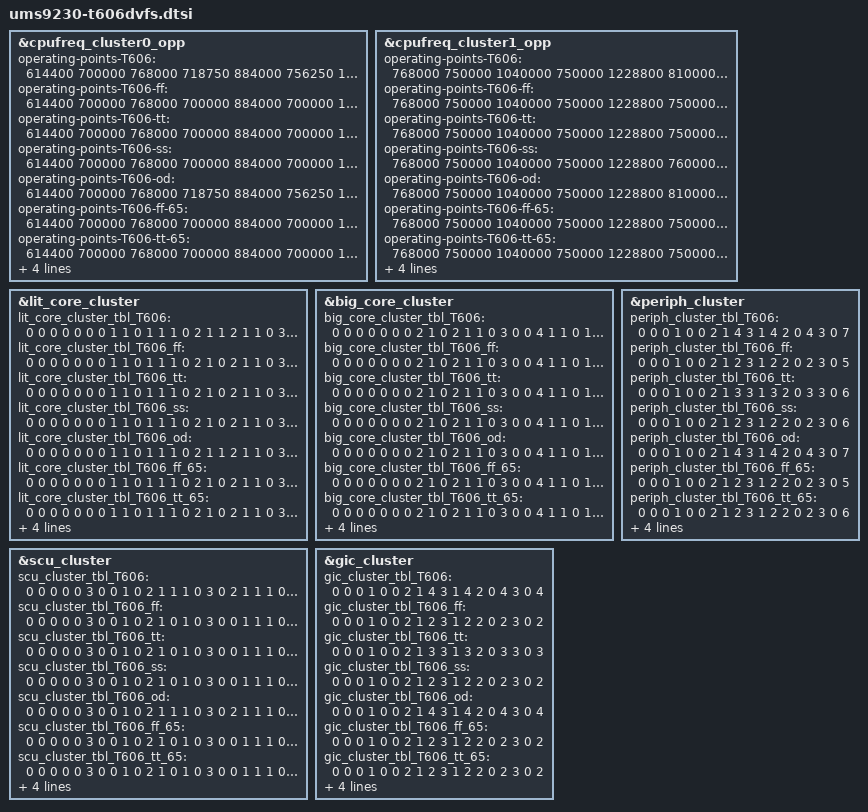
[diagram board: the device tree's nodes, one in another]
// SPDX-License-Identifier: (GPL-2.0+ OR MIT)
/*
 * Unisoc qogirl6 platform T606 SOC DVFS DTS file
 *
 * Copyright (C) 2021, Unisoc Communications Inc.
 */

#include "qogirl6.dtsi"
#include "ums9230.dtsi"

&cpufreq_cluster0_opp {
	/* operating-points-T606-0-0
	 * T606/T616-soc_ver 0-binning 0-temp
	 */
	operating-points-T606 = <
		/* kHZ   uV */
		614400  700000
		768000  718750
		884000  756250
		1040000 787500
		1228800 875000
		1378000 934375
		1536000 996875
		1612000 1018750
	>;

	operating-points-T606-ff = <
		/* kHZ   uV */
		614400  700000
		768000  700000
		884000  700000
		1040000 700000
		1228800 762500
		1378000 815625
		1536000 868750
		1612000 896875
	>;

	operating-points-T606-tt = <
		/* kHZ   uV */
		614400  700000
		768000  700000
		884000  700000
		1040000 725000
		1228800 793750
		1378000 846875
		1536000 900000
		1612000 928125
	>;

	operating-points-T606-ss = <
		/* kHZ   uV */
		614400  700000
		768000  700000
		884000  700000
		1040000 762500
		1228800 831250
		1378000 887500
		1536000 946875
		1612000 975000
	>;

	operating-points-T606-od = <
		/* kHZ   uV */
		614400  700000
		768000  718750
		884000  756250
		1040000 787500
		1228800 875000
		1378000 934375
		1536000 996875
		1612000 1018750
	>;

	operating-points-T606-ff-65 = <
		/* kHZ   uV */
		614400  700000
		768000  700000
		884000  700000
		1040000 700000
		1228800 768750
		1378000 821875
		1536000 881250
		1612000 909375
	>;

	operating-points-T606-tt-65 = <
		/* kHZ   uV */
		614400  700000
		768000  700000
		884000  700000
		1040000 728125
		1228800 800000
		1378000 856250
		1536000 915625
		1612000 943750
	>;

	operating-points-T606-ss-65 = <
		/* kHZ   uV */
		614400  700000
		768000  700000
		884000  700000
		1040000 765625
		1228800 837500
		1378000 896875
		1536000 959375
		1612000 990625
	>;

	operating-points-T606-od-65 = <
		/* kHZ   uV */
		614400  700000
		768000  721875
		884000  759375
		1040000 793750
		1228800 884375
		1378000 946875
		1536000 1012500
		1612000 1037500
	>;
};

&cpufreq_cluster1_opp {
	operating-points-T606 = <
		/* kHZ   uV */
		768000  750000
		1040000 750000
		1228800 810000
		1404000 870000
		1536000 910000
		1612000 930000
	>;

	operating-points-T606-ff = <
		/* kHZ   uV */
		768000  750000
		1040000 750000
		1228800 750000
		1404000 750000
		1536000 780000
		1612000 800000
	>;

	operating-points-T606-tt = <
		/* kHZ   uV */
		768000  750000
		1040000 750000
		1228800 750000
		1404000 780000
		1536000 820000
		1612000 840000
	>;

	operating-points-T606-ss = <
		/* kHZ   uV */
		768000  750000
		1040000 750000
		1228800 760000
		1404000 820000
		1536000 860000
		1612000 880000
	>;

	operating-points-T606-od = <
		/* kHZ   uV */
		768000  750000
		1040000 750000
		1228800 810000
		1404000 870000
		1536000 910000
		1612000 930000
	>;

	operating-points-T606-ff-65 = <
		/* kHZ   uV */
		768000  750000
		1040000 750000
		1228800 750000
		1404000 750000
		1536000 780000
		1612000 810000
	>;

	operating-points-T606-tt-65 = <
		/* kHZ   uV */
		768000  750000
		1040000 750000
		1228800 750000
		1404000 780000
		1536000 820000
		1612000 850000
	>;

	operating-points-T606-ss-65 = <
		/* kHZ   uV */
		768000  750000
		1040000 750000
		1228800 760000
		1404000 820000
		1536000 870000
		1612000 890000
	>;

	operating-points-T606-od-65 = <
		/* kHZ   uV */
		768000  750000
		1040000 750000
		1228800 820000
		1404000 870000
		1536000 920000
		1612000 940000
	>;
};

&lit_core_cluster {
	/* lit_core_cluster_tbl_T606_0_0
	 * T606/T616-soc_ver 0-binning 0-temp
	 * sel, div, vol, vote_scu, vote_peri, vote_gic, mpllx
	 */
	lit_core_cluster_tbl_T606 = <
		0 0 0 0 0 0 0
		1 1 0 1 1 1 0
		2 1 1 2 1 1 0
		3 0 2 3 1 1 0
		3 0 3 4 1 1 1
		1 0 4 5 1 1 0
		3 0 5 6 4 4 2
		2 0 6 7 4 4 0
		3 0 7 8 4 5 3
		3 0 7 8 4 5 3
		3 0 7 8 4 5 3
	>;

	lit_core_cluster_tbl_T606_ff = <
		0 0 0 0 0 0 0
		1 1 0 1 1 1 0
		2 1 0 2 1 1 0
		3 0 0 3 1 1 0
		3 0 0 4 1 1 1
		1 0 1 5 1 1 0
		3 0 2 6 4 4 2
		2 0 3 7 4 4 0
		3 0 4 8 4 5 3
		3 0 4 8 4 5 3
		3 0 4 8 4 5 3
	>;

	lit_core_cluster_tbl_T606_tt = <
		0 0 0 0 0 0 0
		1 1 0 1 1 1 0
		2 1 0 2 1 1 0
		3 0 0 3 1 1 0
		3 0 1 4 1 1 1
		1 0 2 5 1 1 0
		3 0 3 6 4 4 2
		2 0 4 7 4 4 0
		3 0 5 8 4 5 3
		3 0 5 8 4 5 3
		3 0 5 8 4 5 3
	>;

	lit_core_cluster_tbl_T606_ss = <
		0 0 0 0 0 0 0
		1 1 0 1 1 1 0
		2 1 0 2 1 1 0
		3 0 0 3 1 1 0
		3 0 1 4 1 1 1
		1 0 2 5 1 1 0
		3 0 3 6 4 4 2
		2 0 4 7 4 4 0
		3 0 5 8 4 5 3
		3 0 5 8 4 5 3
		3 0 5 8 4 5 3
	>;

	lit_core_cluster_tbl_T606_od = <
		0 0 0 0 0 0 0
		1 1 0 1 1 1 0
		2 1 1 2 1 1 0
		3 0 2 3 1 1 0
		3 0 3 4 1 1 1
		1 0 4 5 1 1 0
		3 0 5 6 4 4 2
		2 0 6 7 4 4 0
		3 0 7 8 4 5 3
		3 0 7 8 4 5 3
		3 0 7 8 4 5 3
	>;

	lit_core_cluster_tbl_T606_ff_65 = <
		0 0 0 0 0 0 0
		1 1 0 1 1 1 0
		2 1 0 2 1 1 0
		3 0 0 3 1 1 0
		3 0 0 4 1 1 1
		1 0 1 5 1 1 0
		3 0 2 6 4 4 2
		2 0 3 7 4 4 0
		3 0 4 8 4 5 3
		3 0 4 8 4 5 3
		3 0 4 8 4 5 3
	>;

	lit_core_cluster_tbl_T606_tt_65 = <
		0 0 0 0 0 0 0
		1 1 0 1 1 1 0
		2 1 0 2 1 1 0
		3 0 0 3 1 1 0
		3 0 1 4 1 1 1
		1 0 2 5 1 1 0
		3 0 3 6 4 4 2
		2 0 4 7 4 4 0
		3 0 5 8 4 5 3
		3 0 5 8 4 5 3
		3 0 5 8 4 5 3
	>;

	lit_core_cluster_tbl_T606_ss_65 = <
		0 0 0 0 0 0 0
		1 1 0 1 1 1 0
		2 1 0 2 1 1 0
		3 0 0 3 1 1 0
		3 0 1 4 1 1 1
		1 0 2 5 1 1 0
		3 0 3 6 4 4 2
		2 0 4 7 4 4 0
		3 0 5 8 4 5 3
		3 0 5 8 4 5 3
		3 0 5 8 4 5 3
	>;

	lit_core_cluster_tbl_T606_od_65 = <
		0 0 0 0 0 0 0
		1 1 0 1 1 1 0
		2 1 1 2 1 1 0
		3 0 2 3 1 1 0
		3 0 3 4 1 1 1
		1 0 4 5 1 1 0
		3 0 5 6 4 4 2
		2 0 6 7 4 4 0
		3 0 7 8 4 5 3
		3 0 7 8 4 5 3
		3 0 7 8 4 5 3
	>;
};

&big_core_cluster {
	/* sel, div, vol, vote_scu, vote_peri, vote_gic, mpllx */
	big_core_cluster_tbl_T606 = <
		0 0 0 0 0 0 0
		2 1 0 2 1 1 0
		3 0 0 4 1 1 0
		1 0 1 4 1 1 0
		3 0 2 6 4 4 1
		2 0 3 7 4 4 0
		3 0 4 8 4 5 2
		3 0 4 8 4 5 2
		3 0 4 8 4 5 2
		3 0 4 8 4 5 2
	>;

	big_core_cluster_tbl_T606_ff = <
		0 0 0 0 0 0 0
		2 1 0 2 1 1 0
		3 0 0 4 1 1 0
		1 0 0 4 1 1 0
		3 0 0 6 4 4 1
		2 0 1 7 4 4 0
		3 0 2 8 4 5 2
		3 0 2 8 4 5 2
		3 0 2 8 4 5 2
		3 0 2 8 4 5 2
	>;

	big_core_cluster_tbl_T606_tt = <
		0 0 0 0 0 0 0
		2 1 0 2 1 1 0
		3 0 0 4 1 1 0
		1 0 0 4 1 1 0
		3 0 1 6 4 4 1
		2 0 2 7 4 4 0
		3 0 3 8 4 5 2
		3 0 3 8 4 5 2
		3 0 3 8 4 5 2
		3 0 3 8 4 5 2
	>;

	big_core_cluster_tbl_T606_ss = <
		0 0 0 0 0 0 0
		2 1 0 2 1 1 0
		3 0 0 4 1 1 0
		1 0 1 4 1 1 0
		3 0 2 6 4 4 1
		2 0 3 7 4 4 0
		3 0 4 8 4 5 2
		3 0 4 8 4 5 2
		3 0 4 8 4 5 2
		3 0 4 8 4 5 2
	>;

	big_core_cluster_tbl_T606_od = <
		0 0 0 0 0 0 0
		2 1 0 2 1 1 0
		3 0 0 4 1 1 0
		1 0 1 4 1 1 0
		3 0 2 6 4 4 1
		2 0 3 7 4 4 0
		3 0 4 8 4 5 2
		3 0 4 8 4 5 2
		3 0 4 8 4 5 2
		3 0 4 8 4 5 2
	>;

	big_core_cluster_tbl_T606_ff_65 = <
		0 0 0 0 0 0 0
		2 1 0 2 1 1 0
		3 0 0 4 1 1 0
		1 0 0 4 1 1 0
		3 0 0 6 4 4 1
		2 0 1 7 4 4 0
		3 0 2 8 4 5 2
		3 0 2 8 4 5 2
		3 0 2 8 4 5 2
		3 0 2 8 4 5 2
	>;

	big_core_cluster_tbl_T606_tt_65 = <
		0 0 0 0 0 0 0
		2 1 0 2 1 1 0
		3 0 0 4 1 1 0
		1 0 0 4 1 1 0
		3 0 1 6 4 4 1
		2 0 2 7 4 4 0
		3 0 3 8 4 5 2
		3 0 3 8 4 5 2
		3 0 3 8 4 5 2
		3 0 3 8 4 5 2
	>;

	big_core_cluster_tbl_T606_ss_65 = <
		0 0 0 0 0 0 0
		2 1 0 2 1 1 0
		3 0 0 4 1 1 0
		1 0 1 4 1 1 0
		3 0 2 6 4 4 1
		2 0 3 7 4 4 0
		3 0 4 8 4 5 2
		3 0 4 8 4 5 2
		3 0 4 8 4 5 2
		3 0 4 8 4 5 2
	>;

	big_core_cluster_tbl_T606_od_65 = <
		0 0 0 0 0 0 0
		2 1 0 2 1 1 0
		3 0 0 4 1 1 0
		1 0 1 4 1 1 0
		3 0 2 6 4 4 1
		2 0 3 7 4 4 0
		3 0 4 8 4 5 2
		3 0 4 8 4 5 2
		3 0 4 8 4 5 2
		3 0 4 8 4 5 2
	>;
};

&scu_cluster {
	/* sel, div, vol, ace_div, mpllx */
	scu_cluster_tbl_T606 = <
		0 0 0 0 0
		3 0 0 1 0
		2 1 1 1 0
		3 0 2 1 1
		1 0 3 1 0
		3 0 4 1 2
		3 0 5 1 3
		2 0 6 1 0
		3 0 7 1 4
		3 0 7 1 4
		3 0 7 1 4
	>;

	scu_cluster_tbl_T606_ff = <
		0 0 0 0 0
		3 0 0 1 0
		2 1 0 1 0
		3 0 0 1 1
		1 0 0 1 0
		3 0 1 1 2
		3 0 2 1 3
		2 0 3 1 0
		3 0 4 1 4
		3 0 4 1 4
		3 0 4 1 4
	>;

	scu_cluster_tbl_T606_tt = <
		0 0 0 0 0
		3 0 0 1 0
		2 1 0 1 0
		3 0 0 1 1
		1 0 1 1 0
		3 0 2 1 2
		3 0 3 1 3
		2 0 4 1 0
		3 0 5 1 4
		3 0 5 1 4
		3 0 5 1 4
	>;

	scu_cluster_tbl_T606_ss = <
		0 0 0 0 0
		3 0 0 1 0
		2 1 0 1 0
		3 0 0 1 1
		1 0 1 1 0
		3 0 2 1 2
		3 0 3 1 3
		2 0 4 1 0
		3 0 5 1 4
		3 0 5 1 4
		3 0 5 1 4
	>;

	scu_cluster_tbl_T606_od = <
		0 0 0 0 0
		3 0 0 1 0
		2 1 1 1 0
		3 0 2 1 1
		1 0 3 1 0
		3 0 4 1 2
		3 0 5 1 3
		2 0 6 1 0
		3 0 7 1 4
		3 0 7 1 4
		3 0 7 1 4
	>;

	scu_cluster_tbl_T606_ff_65 = <
		0 0 0 0 0
		3 0 0 1 0
		2 1 0 1 0
		3 0 0 1 1
		1 0 0 1 0
		3 0 1 1 2
		3 0 2 1 3
		2 0 3 1 0
		3 0 4 1 4
		3 0 4 1 4
		3 0 4 1 4
	>;

	scu_cluster_tbl_T606_tt_65 = <
		0 0 0 0 0
		3 0 0 1 0
		2 1 0 1 0
		3 0 0 1 1
		1 0 1 1 0
		3 0 2 1 2
		3 0 3 1 3
		2 0 4 1 0
		3 0 5 1 4
		3 0 5 1 4
		3 0 5 1 4
	>;

	scu_cluster_tbl_T606_ss_65 = <
		0 0 0 0 0
		3 0 0 1 0
		2 1 0 1 0
		3 0 0 1 1
		1 0 1 1 0
		3 0 2 1 2
		3 0 3 1 3
		2 0 4 1 0
		3 0 5 1 4
		3 0 5 1 4
		3 0 5 1 4
	>;

	scu_cluster_tbl_T606_od_65 = <
		0 0 0 0 0
		3 0 0 1 0
		2 1 1 1 0
		3 0 2 1 1
		1 0 3 1 0
		3 0 4 1 2
		3 0 5 1 3
		2 0 6 1 0
		3 0 7 1 4
		3 0 7 1 4
		3 0 7 1 4
	>;
};

&periph_cluster{
	/* sel, div, vol */
	periph_cluster_tbl_T606 = <
		0 0 0
		1 0 0
		2 1 4
		3 1 4
		2 0 4
		3 0 7
	>;

	periph_cluster_tbl_T606_ff = <
		0 0 0
		1 0 0
		2 1 2
		3 1 2
		2 0 2
		3 0 5
	>;

	periph_cluster_tbl_T606_tt = <
		0 0 0
		1 0 0
		2 1 3
		3 1 3
		2 0 3
		3 0 6
	>;

	periph_cluster_tbl_T606_ss = <
		0 0 0
		1 0 0
		2 1 2
		3 1 2
		2 0 2
		3 0 6
	>;

	periph_cluster_tbl_T606_od = <
		0 0 0
		1 0 0
		2 1 4
		3 1 4
		2 0 4
		3 0 7
	>;

	periph_cluster_tbl_T606_ff_65 = <
		0 0 0
		1 0 0
		2 1 2
		3 1 2
		2 0 2
		3 0 5
	>;

	periph_cluster_tbl_T606_tt_65 = <
		0 0 0
		1 0 0
		2 1 2
		3 1 2
		2 0 2
		3 0 6
	>;

	periph_cluster_tbl_T606_ss_65 = <
		0 0 0
		1 0 0
		2 1 2
		3 1 2
		2 0 2
		3 0 6
	>;

	periph_cluster_tbl_T606_od_65 = <
		0 0 0
		1 0 0
		2 1 4
		3 1 4
		2 0 4
		3 0 6
	>;
};

&gic_cluster{
	/* sel, div, vol */
	gic_cluster_tbl_T606 = <
		0 0 0
		1 0 0
		2 1 4
		3 1 4
		2 0 4
		3 0 4
	>;

	gic_cluster_tbl_T606_ff = <
		0 0 0
		1 0 0
		2 1 2
		3 1 2
		2 0 2
		3 0 2
	>;

	gic_cluster_tbl_T606_tt = <
		0 0 0
		1 0 0
		2 1 3
		3 1 3
		2 0 3
		3 0 3
	>;

	gic_cluster_tbl_T606_ss = <
		0 0 0
		1 0 0
		2 1 2
		3 1 2
		2 0 2
		3 0 2
	>;

	gic_cluster_tbl_T606_od = <
		0 0 0
		1 0 0
		2 1 4
		3 1 4
		2 0 4
		3 0 4
	>;

	gic_cluster_tbl_T606_ff_65 = <
		0 0 0
		1 0 0
		2 1 2
		3 1 2
		2 0 2
		3 0 2
	>;

	gic_cluster_tbl_T606_tt_65 = <
		0 0 0
		1 0 0
		2 1 2
		3 1 2
		2 0 2
		3 0 2
	>;

	gic_cluster_tbl_T606_ss_65 = <
		0 0 0
		1 0 0
		2 1 2
		3 1 2
		2 0 2
		3 0 2
	>;

	gic_cluster_tbl_T606_od_65 = <
		0 0 0
		1 0 0
		2 1 4
		3 1 4
		2 0 4
		3 0 4
	>;
};
